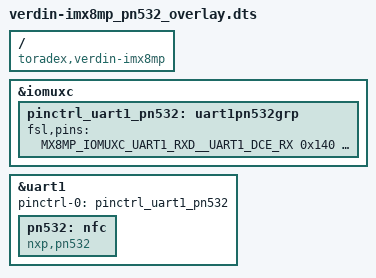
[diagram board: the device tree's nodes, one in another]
/dts-v1/;
/plugin/;

#include "imx8mp-pinfunc.h"

/ {
    compatible = "toradex,verdin-imx8mp";
};

&iomuxc {
    /* Định nghĩa pinctrl riêng để không bị ảnh hưởng bởi mặc định */
    pinctrl_uart1_pn532: uart1pn532grp {
        fsl,pins = <
            MX8MP_IOMUXC_UART1_RXD__UART1_DCE_RX    0x140
            MX8MP_IOMUXC_UART1_TXD__UART1_DCE_TX    0x140
        >;
    };
};

&uart1 {
    /* Gán group pin mới */
    pinctrl-names = "default";
    pinctrl-0 = <&pinctrl_uart1_pn532>;
    status = "okay";
    /* Tắt flow control để phù hợp với kết nối 2 dây RX/TX */
    /delete-property/ uart-has-rtscts;

    pn532: nfc {
        compatible = "nxp,pn532";
    };
};
